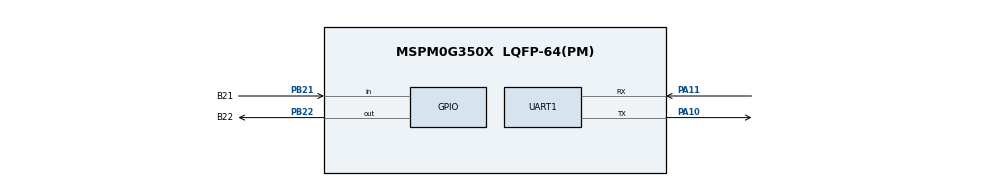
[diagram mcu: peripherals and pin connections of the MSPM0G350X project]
/**
 * @cliArgs --device "MSPM0G350X" --part "Default" --package "LQFP-64(PM)" --product "mspm0_sdk@2.05.00.05"
 * @versions {"tool":"1.24.0+4150"}
 */

/**
 * Import the modules used in this configuration.
 */
const GPIO   = scripting.addModule("/ti/driverlib/GPIO", {}, false);
const GPIO1  = GPIO.addInstance();
const GPIO2  = GPIO.addInstance();
const SYSCTL = scripting.addModule("/ti/driverlib/SYSCTL");
const TIMER  = scripting.addModule("/ti/driverlib/TIMER", {}, false);
const TIMER1 = TIMER.addInstance();
const TIMER2 = TIMER.addInstance();
const UART   = scripting.addModule("/ti/driverlib/UART", {}, false);
const UART1  = UART.addInstance();

/**
 * Write custom configuration values to the imported modules.
 */
const divider9       = system.clockTree["UDIV"];
divider9.divideValue = 2;

const gate7  = system.clockTree["MFCLKGATE"];
gate7.enable = true;

const multiplier2         = system.clockTree["PLL_QDIV"];
multiplier2.multiplyValue = 4;

const mux4       = system.clockTree["EXHFMUX"];
mux4.inputSelect = "EXHFMUX_XTAL";

const mux8       = system.clockTree["HSCLKMUX"];
mux8.inputSelect = "HSCLKMUX_SYSPLL0";

const mux12       = system.clockTree["SYSPLLMUX"];
mux12.inputSelect = "zSYSPLLMUX_HFCLK";

const pinFunction4        = system.clockTree["HFXT"];
pinFunction4.inputFreq    = 40;
pinFunction4.enable       = true;
pinFunction4.HFCLKMonitor = true;
pinFunction4.HFXTStartup  = 10;

GPIO1.$name                               = "KEY";
GPIO1.port                                = "PORTB";
GPIO1.associatedPins[0].$name             = "B21";
GPIO1.associatedPins[0].direction         = "INPUT";
GPIO1.associatedPins[0].ioStructure       = "SD";
GPIO1.associatedPins[0].internalResistor  = "PULL_UP";
GPIO1.associatedPins[0].assignedPin       = "21";
GPIO1.associatedPins[0].polarity          = "RISE";
GPIO1.associatedPins[0].interruptPriority = "3";
GPIO1.associatedPins[0].pin.$assign       = "PB21";

const Board = scripting.addModule("/ti/driverlib/Board", {}, false);

GPIO2.$name                              = "LED";
GPIO2.port                               = "PORTB";
GPIO2.associatedPins[0].$name            = "B22";
GPIO2.associatedPins[0].ioStructure      = "SD";
GPIO2.associatedPins[0].internalResistor = "PULL_DOWN";
GPIO2.associatedPins[0].assignedPin      = "22";
GPIO2.associatedPins[0].pin.$assign      = "PB22";

SYSCTL.forceDefaultClkConfig = true;
SYSCTL.clockTreeEn           = true;
scripting.suppress("For best practices when the CPUCLK is running at 32MHz and above, clear the flash status bit using DL_FlashCTL_executeClearStatus\\(\\) before executing any flash operation\\. Otherwise there may be false positives\\.", SYSCTL);

TIMER1.timerPeriod        = "1us";
TIMER1.timerClkDiv        = 8;
TIMER1.$name              = "TIM_delay_us";
TIMER1.timerClkPrescale   = 10;
TIMER1.peripheral.$assign = "TIMA0";

TIMER2.$name            = "TIM_delay_ms";
TIMER2.timerClkDiv      = 8;
TIMER2.timerClkPrescale = 250;
TIMER2.timerClkSrc      = "MFCLK";
TIMER2.timerPeriod      = "1 ms";

UART1.enabledInterrupts                = ["RX"];
UART1.interruptPriority                = "3";
UART1.$name                            = "UART_DEBUG";
UART1.targetBaudRate                   = 115200;
UART1.peripheral.$assign               = "UART0";
UART1.peripheral.rxPin.$assign         = "PA11";
UART1.peripheral.txPin.$assign         = "PA10";
UART1.txPinConfig.$name                = "ti_driverlib_gpio_GPIOPinGeneric0";
UART1.txPinConfig.direction            = scripting.forceWrite("OUTPUT");
UART1.txPinConfig.hideOutputInversion  = scripting.forceWrite(false);
UART1.txPinConfig.onlyInternalResistor = scripting.forceWrite(false);
UART1.txPinConfig.passedPeripheralType = scripting.forceWrite("Digital");
UART1.rxPinConfig.$name                = "ti_driverlib_gpio_GPIOPinGeneric1";
UART1.rxPinConfig.hideOutputInversion  = scripting.forceWrite(false);
UART1.rxPinConfig.onlyInternalResistor = scripting.forceWrite(false);
UART1.rxPinConfig.passedPeripheralType = scripting.forceWrite("Digital");

/**
 * Pinmux solution for unlocked pins/peripherals. This ensures that minor changes to the automatic solver in a future
 * version of the tool will not impact the pinmux you originally saw.  These lines can be completely deleted in order to
 * re-solve from scratch.
 */
pinFunction4.peripheral.$suggestSolution           = "SYSCTL";
pinFunction4.peripheral.hfxInPin.$suggestSolution  = "PA5";
pinFunction4.peripheral.hfxOutPin.$suggestSolution = "PA6";
Board.peripheral.$suggestSolution                  = "DEBUGSS";
Board.peripheral.swclkPin.$suggestSolution         = "PA20";
Board.peripheral.swdioPin.$suggestSolution         = "PA19";
TIMER2.peripheral.$suggestSolution                 = "TIMA1";
